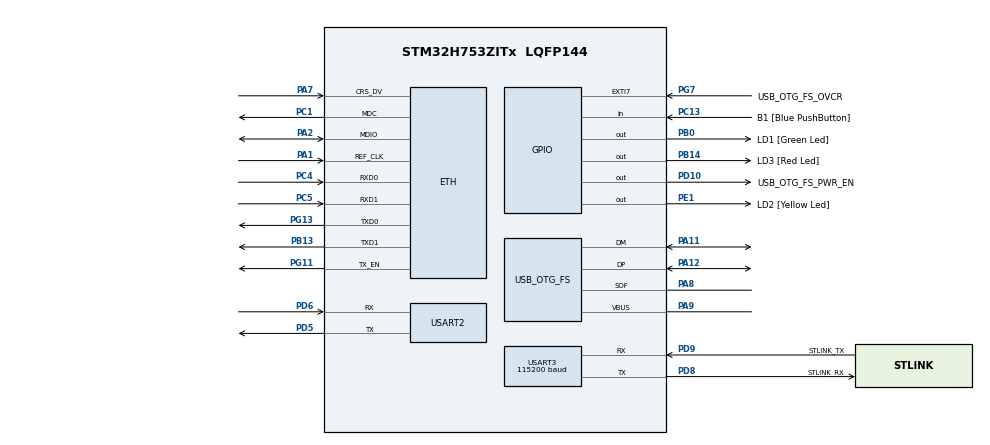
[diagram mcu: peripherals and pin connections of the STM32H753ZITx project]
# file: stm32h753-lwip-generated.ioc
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CORTEX_M7.AccessPermission-Cortex_Memory_Protection_Unit_Region0_Settings=MPU_REGION_NO_ACCESS
CORTEX_M7.AccessPermission-Cortex_Memory_Protection_Unit_Region1_Settings=MPU_REGION_FULL_ACCESS
CORTEX_M7.AccessPermission-Cortex_Memory_Protection_Unit_Region2_Settings=MPU_REGION_FULL_ACCESS
CORTEX_M7.BaseAddress-Cortex_Memory_Protection_Unit_Region0_Settings=0
CORTEX_M7.BaseAddress-Cortex_Memory_Protection_Unit_Region1_Settings=__LWIP_RX_TX_DESCRIPTORS_START__
CORTEX_M7.BaseAddress-Cortex_Memory_Protection_Unit_Region2_Settings=__LWIP_POOL_AND_HEAP_START__
CORTEX_M7.CPU_DCache=Enabled
CORTEX_M7.CPU_ICache=Enabled
CORTEX_M7.DisableExec-Cortex_Memory_Protection_Unit_Region0_Settings=MPU_INSTRUCTION_ACCESS_DISABLE
CORTEX_M7.DisableExec-Cortex_Memory_Protection_Unit_Region1_Settings=MPU_INSTRUCTION_ACCESS_DISABLE
CORTEX_M7.DisableExec-Cortex_Memory_Protection_Unit_Region2_Settings=MPU_INSTRUCTION_ACCESS_DISABLE
CORTEX_M7.Enable-Cortex_Memory_Protection_Unit_Region0_Settings=MPU_REGION_ENABLE
CORTEX_M7.Enable-Cortex_Memory_Protection_Unit_Region1_Settings=MPU_REGION_ENABLE
CORTEX_M7.Enable-Cortex_Memory_Protection_Unit_Region2_Settings=MPU_REGION_ENABLE
CORTEX_M7.IsBufferable-Cortex_Memory_Protection_Unit_Region0_Settings=MPU_ACCESS_NOT_BUFFERABLE
CORTEX_M7.IsBufferable-Cortex_Memory_Protection_Unit_Region1_Settings=MPU_ACCESS_BUFFERABLE
CORTEX_M7.IsShareable-Cortex_Memory_Protection_Unit_Region0_Settings=MPU_ACCESS_SHAREABLE
CORTEX_M7.IsShareable-Cortex_Memory_Protection_Unit_Region1_Settings=MPU_ACCESS_SHAREABLE
CORTEX_M7.IsShareable-Cortex_Memory_Protection_Unit_Region2_Settings=MPU_ACCESS_SHAREABLE
CORTEX_M7.MPU_Control=MPU_PRIVILEGED_DEFAULT
CORTEX_M7.Size-Cortex_Memory_Protection_Unit_Region0_Settings=MPU_REGION_SIZE_4GB
CORTEX_M7.Size-Cortex_Memory_Protection_Unit_Region1_Settings=MPU_REGION_SIZE_1KB
CORTEX_M7.Size-Cortex_Memory_Protection_Unit_Region2_Settings=MPU_REGION_SIZE_32KB
CORTEX_M7.SubRegionDisable-Cortex_Memory_Protection_Unit_Region0_Settings=0x87
CORTEX_M7.TypeExtField-Cortex_Memory_Protection_Unit_Region0_Settings=MPU_TEX_LEVEL0
CORTEX_M7.TypeExtField-Cortex_Memory_Protection_Unit_Region2_Settings=MPU_TEX_LEVEL1
CORTEX_M7.default_mode_Activation=0
ETH.ETH_RX_DESC_CNT=4
ETH.ETH_TX_DESC_CNT=4
ETH.MACAddr=00\:80\:E1\:00\:00\:00
ETH.MediaInterface=HAL_ETH_RMII_MODE
ETH.RxBuffAddress=0x30040200
ETH.RxBuffLen=1524
ETH.RxDescAddress=0x30040000
ETH.TxDescAddress=0x30040060
FREERTOS.Tasks01=defaultTask,24,256,StartDefaultTask,Default,NULL,Dynamic,NULL,NULL
FREERTOS.configMINIMAL_STACK_SIZE=256
FREERTOS.configTOTAL_HEAP_SIZE=24000
FREERTOS.configUSE_NEWLIB_REENTRANT=1
LWIP.BSP.number=1
LWIP.CHECKSUM_BY_HARDWARE=0
LWIP.DEFAULT_THREAD_STACKSIZE=2048
LWIP.GATEWAY_ADDRESS=000.000.000.000
LWIP.IP_ADDRESS=000.000.000.000
LWIP.LWIP_CHECKSUM_CTRL_PER_NETIF=1
LWIP.LWIP_DHCP=0
LWIP.MEM_SIZE=14000
LWIP.NETMASK_ADDRESS=000.000.000.000
LWIP.SLIPIF_THREAD_PRIO=25
LWIP.SLIPIF_THREAD_STACKSIZE=2048
LWIP.TCPIP_THREAD_STACKSIZE=2048
LWIP.Version=v2.1.2_Cube
LWIP0.BSP.STBoard=false
LWIP0.BSP.api=BSP_COMPONENT_DRIVER
LWIP0.BSP.component=LAN8742
LWIP0.BSP.instance=LAN8742
LWIP0.BSP.name=Driver_PHY
LWIP0.BSP.semaphore=S_LAN8742
LWIP0.BSP.solution=LAN8742
Mcu.Family=STM32H7
Mcu.Name=STM32H753ZITx
Mcu.Package=LQFP144
Mcu.UserConstants=__LWIP_RX_TX_DESCRIPTORS_START__,0x30000000;__LWIP_POOL_AND_HEAP_START__,0x30000400
NVIC.ETH_IRQn=true\:5\:0\:false\:false\:true\:true\:true\:true\:true
NVIC.PriorityGroup=NVIC_PRIORITYGROUP_4
NVIC.USART2_IRQn=true\:5\:0\:false\:false\:true\:true\:true\:true\:true
PA1.Mode=RMII
PA1.Signal=ETH_REF_CLK
PA11.Mode=Device_Only
PA11.Signal=USB_OTG_FS_DM
PA12.Mode=Device_Only
PA12.Signal=USB_OTG_FS_DP
PA2.Mode=RMII
PA2.Signal=ETH_MDIO
PA7.Mode=RMII
PA7.Signal=ETH_CRS_DV
PA8.Mode=Activate_SOF_FS
PA8.Signal=USB_OTG_FS_SOF
PA9.Mode=Activate_VBUS
PA9.Signal=USB_OTG_FS_VBUS
PB0.GPIO_Label=LD1 [Green Led]
PB0.Signal=GPIO_Output
PB13.Mode=RMII
PB13.Signal=ETH_TXD1
PB14.GPIO_Label=LD3 [Red Led]
PB14.Signal=GPIO_Output
PC1.Mode=RMII
PC1.Signal=ETH_MDC
PC13.GPIO_Label=B1 [Blue PushButton]
PC13.Signal=GPIO_Input
PC14-OSC32_IN\ (OSC32_IN).Mode=LSE-External-Oscillator
PC14-OSC32_IN\ (OSC32_IN).Signal=RCC_OSC32_IN
PC15-OSC32_OUT\ (OSC32_OUT).Mode=LSE-External-Oscillator
PC15-OSC32_OUT\ (OSC32_OUT).Signal=RCC_OSC32_OUT
PC4.Mode=RMII
PC4.Signal=ETH_RXD0
PC5.Mode=RMII
PC5.Signal=ETH_RXD1
PD10.GPIO_Label=USB_OTG_FS_PWR_EN
PD10.Signal=GPIO_Output
PD5.Mode=Asynchronous
PD5.Signal=USART2_TX
PD6.Mode=Asynchronous
PD6.Signal=USART2_RX
PD8.GPIO_Label=STLINK_RX
PD8.Mode=Asynchronous
PD8.Signal=USART3_TX
PD9.GPIO_Label=STLINK_TX
PD9.Mode=Asynchronous
PD9.Signal=USART3_RX
PE1.GPIO_Label=LD2 [Yellow Led]
PE1.Signal=GPIO_Output
PG11.Mode=RMII
PG11.Signal=ETH_TX_EN
PG13.Mode=RMII
PG13.Signal=ETH_TXD0
PG7.GPIO_Label=USB_OTG_FS_OVCR
PG7.Signal=GPXTI7
PH0-OSC_IN\ (PH0).Mode=HSE-External-Clock-Source
PH0-OSC_IN\ (PH0).Signal=RCC_OSC_IN
PH1-OSC_OUT\ (PH1).Signal=RCC_OSC_OUT
ProjectManager.HeapSize=0x200
ProjectManager.StackSize=0x400
ProjectManager.TargetToolchain=STM32CubeIDE
RCC.ADCFreq_Value=128000000
RCC.APB1Freq_Value=120000000
RCC.APB2Freq_Value=120000000
RCC.APB3Freq_Value=120000000
RCC.APB4Freq_Value=120000000
RCC.CortexFreq_Value=240000000
RCC.DIVM1=4
RCC.DIVM2=1
RCC.DIVN1=240
RCC.DIVN2=32
RCC.DIVQ1=10
RCC.DIVQ2=4
RCC.HCLKFreq_Value=120000000
RCC.HPRE=RCC_HCLK_DIV2
RCC.HSE_VALUE=8000000
RCC.PLLFRACN=0
RCC.PLLSourceVirtual=RCC_PLLSOURCE_HSE
RCC.PWR_Regulator_Voltage_Scale=PWR_REGULATOR_VOLTAGE_SCALE2
RCC.SYSCLKFreq_VALUE=240000000
RCC.SYSCLKSource=RCC_SYSCLKSOURCE_PLLCLK
RCC.USART234578CLockSelection=RCC_USART234578CLKSOURCE_PLL2
RCC.USBFreq_Value=48000000
USART2.OverrunDisableParam=ADVFEATURE_OVERRUN_DISABLE
USART2.VirtualMode-Asynchronous=VM_ASYNC
USART3.AutoBaudRateEnableParam=UART_ADVFEATURE_AUTOBAUDRATE_DISABLE
USART3.BaudRate=115200
USART3.ClockPrescaler=PRESCALER_DIV1
USART3.DMADisableonRxErrorParam=ADVFEATURE_DMA_ENABLEONRXERROR
USART3.DataInvertParam=ADVFEATURE_DATAINV_DISABLE
USART3.FIFOMode=FIFOMODE_DISABLE
USART3.MSBFirstParam=ADVFEATURE_MSBFIRST_DISABLE
USART3.Mode=MODE_TX_RX
USART3.OneBitSampling=UART_ONE_BIT_SAMPLE_DISABLE
USART3.OverSampling=UART_OVERSAMPLING_16
USART3.OverrunDisableParam=ADVFEATURE_OVERRUN_ENABLE
USART3.Parity=PARITY_NONE
USART3.RXFIFOThreshold=RXFIFO_THRESHOLD_1EIGHTHFULL
USART3.RxPinLevelInvertParam=ADVFEATURE_RXINV_DISABLE
USART3.StopBits=STOPBITS_1
USART3.SwapParam=ADVFEATURE_SWAP_DISABLE
USART3.TXFIFOThreshold=TXFIFO_THRESHOLD_1EIGHTHFULL
USART3.TxPinLevelInvertParam=ADVFEATURE_TXINV_DISABLE
USART3.VirtualMode-Asynchronous=VM_ASYNC
USART3.WordLength=WORDLENGTH_8B
USB_OTG_FS.Sof_enable=ENABLE
USB_OTG_FS.VirtualMode=Device_Only
USB_OTG_FS.battery_charging_enable=ENABLE
USB_OTG_FS.low_power_enable=DISABLE
USB_OTG_FS.lpm_enable=DISABLE
USB_OTG_FS.use_dedicated_ep1=DISABLE
USB_OTG_FS.vbus_sensing_enable=ENABLE
VP_FREERTOS_VS_CMSIS_V2.Mode=CMSIS_V2
VP_LWIP_VS_Enabled.Mode=Enabled
board=NUCLEO-H753ZI

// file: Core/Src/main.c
/* USER CODE BEGIN Header */
/**
  ******************************************************************************
  * @file           : main.c
  * @brief          : Main program body
  ******************************************************************************
  * @attention
  *
  * Copyright (c) 2023 STMicroelectronics.
  * All rights reserved.
  *
  * This software is licensed under terms that can be found in the LICENSE file
  * in the root directory of this software component.
  * If no LICENSE file comes with this software, it is provided AS-IS.
  *
  ******************************************************************************
  */
/* USER CODE END Header */
#include "main.h"
#include "cmsis_os.h"
#include "lwip.h"
#include "usart.h"
#include "usb_otg.h"
#include "gpio.h"

/* USER CODE BEGIN Includes */
#include "lwip.h"

/* USER CODE END Includes */

void SystemClock_Config(void);
void PeriphCommonClock_Config(void);
static void MPU_Config(void);
void MX_FREERTOS_Init(void);

int main(void)
{

  /* MPU Configuration--------------------------------------------------------*/
  MPU_Config();

  /* Enable I-Cache---------------------------------------------------------*/
  SCB_EnableICache();

  /* Enable D-Cache---------------------------------------------------------*/
  SCB_EnableDCache();

  /* MCU Configuration--------------------------------------------------------*/

  /* Reset of all peripherals, Initializes the Flash interface and the Systick. */
  HAL_Init();

  /* Configure the system clock */
  SystemClock_Config();

/* Configure the peripherals common clocks */
  PeriphCommonClock_Config();

  /* Initialize all configured peripherals */
  MX_GPIO_Init();
  MX_USART3_UART_Init();
  MX_USB_OTG_FS_PCD_Init();
  MX_USART2_UART_Init();

  /* Init scheduler */
  osKernelInitialize();  /* Call init function for freertos objects (in freertos.c) */
  MX_FREERTOS_Init();

  /* Start scheduler */
  osKernelStart();

  /* We should never get here as control is now taken by the scheduler */
  /* Infinite loop */
  while (1)
  {

  }
}

void SystemClock_Config(void)
{
  RCC_OscInitTypeDef RCC_OscInitStruct = {0};
  RCC_ClkInitTypeDef RCC_ClkInitStruct = {0};

  /** Supply configuration update enable
  */
  HAL_PWREx_ConfigSupply(PWR_LDO_SUPPLY);

  /** Configure the main internal regulator output voltage
  */
  __HAL_PWR_VOLTAGESCALING_CONFIG(PWR_REGULATOR_VOLTAGE_SCALE2);

  while(!__HAL_PWR_GET_FLAG(PWR_FLAG_VOSRDY)) {}

  /** Macro to configure the PLL clock source
  */
  __HAL_RCC_PLL_PLLSOURCE_CONFIG(RCC_PLLSOURCE_HSE);

  /** Initializes the RCC Oscillators according to the specified parameters
  * in the RCC_OscInitTypeDef structure.
  */
  RCC_OscInitStruct.OscillatorType = RCC_OSCILLATORTYPE_HSE;
  RCC_OscInitStruct.HSEState = RCC_HSE_BYPASS;
  RCC_OscInitStruct.PLL.PLLState = RCC_PLL_ON;
  RCC_OscInitStruct.PLL.PLLSource = RCC_PLLSOURCE_HSE;
  RCC_OscInitStruct.PLL.PLLM = 4;
  RCC_OscInitStruct.PLL.PLLN = 240;
  RCC_OscInitStruct.PLL.PLLP = 2;
  RCC_OscInitStruct.PLL.PLLQ = 10;
  RCC_OscInitStruct.PLL.PLLR = 2;
  RCC_OscInitStruct.PLL.PLLRGE = RCC_PLL1VCIRANGE_1;
  RCC_OscInitStruct.PLL.PLLVCOSEL = RCC_PLL1VCOWIDE;
  RCC_OscInitStruct.PLL.PLLFRACN = 0;
  if (HAL_RCC_OscConfig(&RCC_OscInitStruct) != HAL_OK)
  {
    Error_Handler();
  }

  /** Initializes the CPU, AHB and APB buses clocks
  */
  RCC_ClkInitStruct.ClockType = RCC_CLOCKTYPE_HCLK|RCC_CLOCKTYPE_SYSCLK
                              |RCC_CLOCKTYPE_PCLK1|RCC_CLOCKTYPE_PCLK2
                              |RCC_CLOCKTYPE_D3PCLK1|RCC_CLOCKTYPE_D1PCLK1;
  RCC_ClkInitStruct.SYSCLKSource = RCC_SYSCLKSOURCE_PLLCLK;
  RCC_ClkInitStruct.SYSCLKDivider = RCC_SYSCLK_DIV1;
  RCC_ClkInitStruct.AHBCLKDivider = RCC_HCLK_DIV2;
  RCC_ClkInitStruct.APB3CLKDivider = RCC_APB3_DIV1;
  RCC_ClkInitStruct.APB1CLKDivider = RCC_APB1_DIV1;
  RCC_ClkInitStruct.APB2CLKDivider = RCC_APB2_DIV1;
  RCC_ClkInitStruct.APB4CLKDivider = RCC_APB4_DIV1;

  if (HAL_RCC_ClockConfig(&RCC_ClkInitStruct, FLASH_LATENCY_2) != HAL_OK)
  {
    Error_Handler();
  }
}

void PeriphCommonClock_Config(void)
{
  RCC_PeriphCLKInitTypeDef PeriphClkInitStruct = {0};

  /** Initializes the peripherals clock
  */
  PeriphClkInitStruct.PeriphClockSelection = RCC_PERIPHCLK_USART2|RCC_PERIPHCLK_USART3;
  PeriphClkInitStruct.PLL2.PLL2M = 1;
  PeriphClkInitStruct.PLL2.PLL2N = 32;
  PeriphClkInitStruct.PLL2.PLL2P = 2;
  PeriphClkInitStruct.PLL2.PLL2Q = 4;
  PeriphClkInitStruct.PLL2.PLL2R = 2;
  PeriphClkInitStruct.PLL2.PLL2RGE = RCC_PLL2VCIRANGE_3;
  PeriphClkInitStruct.PLL2.PLL2VCOSEL = RCC_PLL2VCOWIDE;
  PeriphClkInitStruct.PLL2.PLL2FRACN = 0;
  PeriphClkInitStruct.Usart234578ClockSelection = RCC_USART234578CLKSOURCE_PLL2;
  if (HAL_RCCEx_PeriphCLKConfig(&PeriphClkInitStruct) != HAL_OK)
  {
    Error_Handler();
  }
}

/* MPU Configuration */

void MPU_Config(void)
{
  MPU_Region_InitTypeDef MPU_InitStruct = {0};

  /* Disables the MPU */
  HAL_MPU_Disable();

  /** Initializes and configures the Region and the memory to be protected
  */
  MPU_InitStruct.Enable = MPU_REGION_ENABLE;
  MPU_InitStruct.Number = MPU_REGION_NUMBER0;
  MPU_InitStruct.BaseAddress = 0;
  MPU_InitStruct.Size = MPU_REGION_SIZE_4GB;
  MPU_InitStruct.SubRegionDisable = 0x87;
  MPU_InitStruct.TypeExtField = MPU_TEX_LEVEL0;
  MPU_InitStruct.AccessPermission = MPU_REGION_NO_ACCESS;
  MPU_InitStruct.DisableExec = MPU_INSTRUCTION_ACCESS_DISABLE;
  MPU_InitStruct.IsShareable = MPU_ACCESS_SHAREABLE;
  MPU_InitStruct.IsCacheable = MPU_ACCESS_NOT_CACHEABLE;
  MPU_InitStruct.IsBufferable = MPU_ACCESS_NOT_BUFFERABLE;

  HAL_MPU_ConfigRegion(&MPU_InitStruct);

  /** Initializes and configures the Region and the memory to be protected
  */
  MPU_InitStruct.Number = MPU_REGION_NUMBER1;
  MPU_InitStruct.BaseAddress = __LWIP_RX_TX_DESCRIPTORS_START__;
  MPU_InitStruct.Size = MPU_REGION_SIZE_1KB;
  MPU_InitStruct.SubRegionDisable = 0x0;
  MPU_InitStruct.AccessPermission = MPU_REGION_FULL_ACCESS;
  MPU_InitStruct.IsBufferable = MPU_ACCESS_BUFFERABLE;

  HAL_MPU_ConfigRegion(&MPU_InitStruct);

  /** Initializes and configures the Region and the memory to be protected
  */
  MPU_InitStruct.Number = MPU_REGION_NUMBER2;
  MPU_InitStruct.BaseAddress = __LWIP_POOL_AND_HEAP_START__;
  MPU_InitStruct.Size = MPU_REGION_SIZE_32KB;
  MPU_InitStruct.TypeExtField = MPU_TEX_LEVEL1;
  MPU_InitStruct.IsBufferable = MPU_ACCESS_NOT_BUFFERABLE;

  HAL_MPU_ConfigRegion(&MPU_InitStruct);
  /* Enables the MPU */
  HAL_MPU_Enable(MPU_PRIVILEGED_DEFAULT);

}

void Error_Handler(void)
{
  __disable_irq();
  while (1)
  {
  }
}

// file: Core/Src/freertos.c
/* USER CODE BEGIN Header */
/**
  ******************************************************************************
  * File Name          : freertos.c
  * Description        : Code for freertos applications
  ******************************************************************************
  * @attention
  *
  * Copyright (c) 2023 STMicroelectronics.
  * All rights reserved.
  *
  * This software is licensed under terms that can be found in the LICENSE file
  * in the root directory of this software component.
  * If no LICENSE file comes with this software, it is provided AS-IS.
  *
  ******************************************************************************
  */
/* USER CODE END Header */

#include "FreeRTOS.h"
#include "task.h"
#include "main.h"
#include "cmsis_os.h"

/* USER CODE BEGIN Includes */

#include "debug.h"
#include "lwip.h"
#include "udp_echoserver.h"
/* USER CODE END Includes */

/* Definitions for defaultTask */
osThreadId_t defaultTaskHandle;
const osThreadAttr_t defaultTask_attributes = {
  .name = "defaultTask",
  .stack_size = 256 * 4,
  .priority = (osPriority_t) osPriorityNormal,
};

void StartDefaultTask(void *argument);

extern void MX_LWIP_Init(void);
void MX_FREERTOS_Init(void); /* (MISRA C 2004 rule 8.1) */

void MX_FREERTOS_Init(void) {

  /* Create the thread(s) */
  /* creation of defaultTask */
  defaultTaskHandle = osThreadNew(StartDefaultTask, NULL, &defaultTask_attributes);

}

void StartDefaultTask(void *argument)
{
  /* init code for LWIP */
  MX_LWIP_Init();
  /* USER CODE BEGIN StartDefaultTask */
	ip4_addr_t ipaddr;

	IP_ADDR4(&ipaddr, 192, 168, 69, 10);
	udp_echoserver_init(&ipaddr);

	IP_ADDR4(&ipaddr, 192, 168, 70, 10);
	udp_echoserver_init(&ipaddr);

  /* Infinite loop */
  for(;;)
  {
    osDelay(1);
  }
  /* USER CODE END StartDefaultTask */
}
